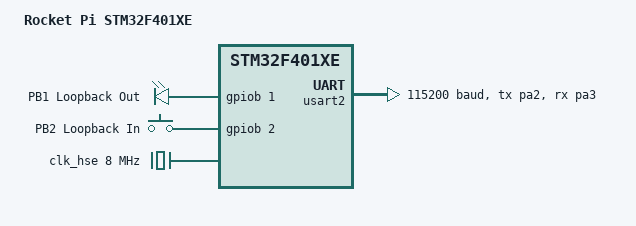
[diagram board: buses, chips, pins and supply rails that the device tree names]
/dts-v1/;
#include <st/f4/stm32f401Xe.dtsi>
#include <st/f4/stm32f401r(d-e)tx-pinctrl.dtsi>

/ {
	model = "Rocket Pi STM32F401XE";
	compatible = "others,rocket-pi-stm32f401xe";

	chosen {
		zephyr,console = &usart2;
		zephyr,shell-uart = &usart2;
		zephyr,sram = &sram0;
		zephyr,flash = &flash0;
	};

	aliases {
		loopback-out = &loopback_out;
		loopback-in = &loopback_in;
		led0 = &loopback_out;
	};

	loopback_outputs {
		compatible = "gpio-leds";

		loopback_out: loopback_out {
			gpios = <&gpiob 1 GPIO_ACTIVE_HIGH>;
			label = "PB1 Loopback Out";
		};
	};

	loopback_inputs {
		compatible = "gpio-keys";

		loopback_in: loopback_in {
			gpios = <&gpiob 2 GPIO_ACTIVE_HIGH>;
			label = "PB2 Loopback In";
		};
	};
};

&clk_hse {
	clock-frequency = <DT_FREQ_M(8)>;
	status = "okay";
};

&pll {
	div-m = <8>;
	mul-n = <336>;
	div-p = <4>;
	div-q = <7>;
	clocks = <&clk_hse>;
	status = "okay";
};

&rcc {
	clocks = <&pll>;
	clock-frequency = <DT_FREQ_M(84)>;
	ahb-prescaler = <1>;
	apb1-prescaler = <2>;
	apb2-prescaler = <1>;
};

&usart2 {
	pinctrl-0 = <&usart2_tx_pa2 &usart2_rx_pa3>;
	pinctrl-names = "default";
	current-speed = <115200>;
	status = "okay";
};

&gpiob {
	status = "okay";
};

&flash0 {
	partitions {
		compatible = "fixed-partitions";
		#address-cells = <1>;
		#size-cells = <1>;

		boot_partition: partition@0 {
			label = "image-0";
			reg = <0x00000000 DT_SIZE_K(512)>;
		};
	};
};
